AUTOSAR XML (schema 4-0-3)
standard types defined: Boolean, uint8, UInt16, UInt32, UInt8
package /AUTOSAR_Platform/DataConstrs
  range DC_Boolean: raw 0..1
  range DC_UInt16: raw 0..65535
  range DC_UInt8: raw 0..255
package /PATAC/Facility/DataTypes/Implementation
  compu method COMPU_Boolean: 0=FALSE, 1=TRUE
  unit NoUnit: factor-si-to-unit=1, offset-si-to-unit=0
package /PATAC/MSM/ComponentTypes
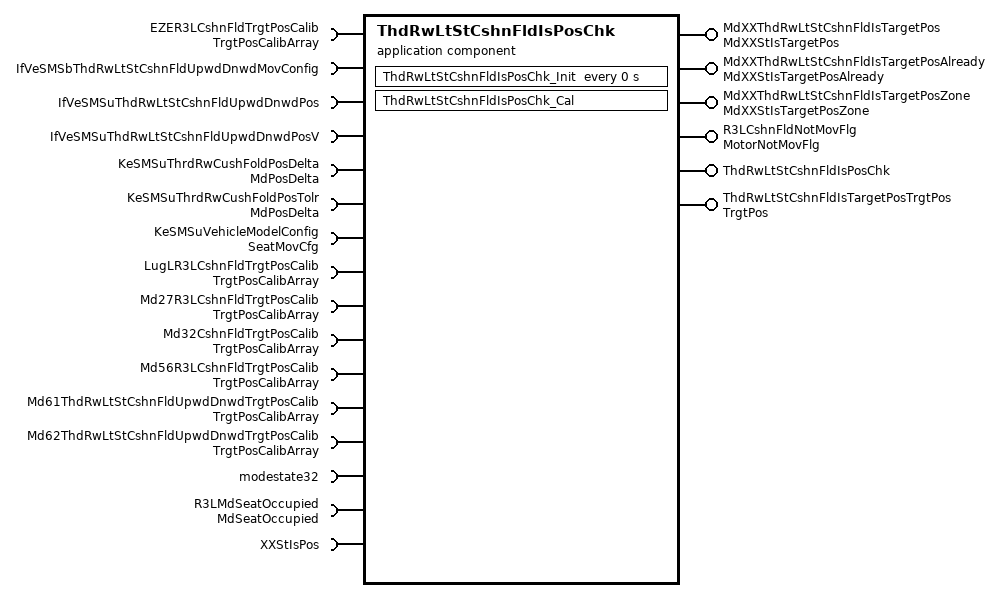
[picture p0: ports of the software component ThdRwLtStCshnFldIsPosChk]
  application sw component type ThdRwLtStCshnFldIsPosChk
    6 x provide port:
      MdXXThdRwLtStCshnFldIsTargetPos: nonqueued-sender-com-spec=data-element=MdXXStIsTargetPos/Val, provided-interface=MdXXStIsTargetPos
      MdXXThdRwLtStCshnFldIsTargetPosAlready: nonqueued-sender-com-spec=data-element=MdXXStIsTargetPosAlready/Val, provided-interface=MdXXStIsTargetPosAlready
      MdXXThdRwLtStCshnFldIsTargetPosZone: nonqueued-sender-com-spec=data-element=MdXXStIsTargetPosZone/Val, provided-interface=MdXXStIsTargetPosZone
      R3LCshnFldNotMovFlg: nonqueued-sender-com-spec{data-element=MotorNotMovFlg/Val, init-value=0}, provided-interface=MotorNotMovFlg
      ThdRwLtStCshnFldIsPosChk: server-com-spec{operation=Cal, queue-length=1}, provided-interface=ThdRwLtStCshnFldIsPosChk
      ThdRwLtStCshnFldIsTargetPosTrgtPos: nonqueued-sender-com-spec{data-element=TrgtPos/Val, init-value=4095}, provided-interface=TrgtPos
    16 x require port:
      EZER3LCshnFldTrgtPosCalib: nonqueued-receiver-com-spec{data-element=TrgtPosArray, filter=data-filter-type=ALWAYS, init-value=[4095, 4095, 4095]}, required-interface=TrgtPosCalibArray
      IfVeSMSbThdRwLtStCshnFldUpwdDnwdMovConfig: nonqueued-receiver-com-spec{data-element=IfVeSMSbThdRwLtStCshnFldUpwdDnwdMovConfig/Val, filter=data-filter-type=ALWAYS, init-value=0}, required-interface=IfVeSMSbThdRwLtStCshnFldUpwdDnwdMovConfig
      IfVeSMSuThdRwLtStCshnFldUpwdDnwdPos: nonqueued-receiver-com-spec{data-element=IfVeSMSuThdRwLtStCshnFldUpwdDnwdPos/Val, filter=data-filter-type=ALWAYS, init-value=0}, required-interface=IfVeSMSuThdRwLtStCshnFldUpwdDnwdPos
      IfVeSMSuThdRwLtStCshnFldUpwdDnwdPosV: nonqueued-receiver-com-spec{data-element=IfVeSMSuThdRwLtStCshnFldUpwdDnwdPosV/Val, filter=data-filter-type=ALWAYS, init-value=0}, required-interface=IfVeSMSuThdRwLtStCshnFldUpwdDnwdPosV
      KeSMSuThrdRwCushFoldPosDelta: parameter-require-com-spec{init-value=150, parameter=MdPosDelta/Val}, required-interface=MdPosDelta
      KeSMSuThrdRwCushFoldPosTolr: parameter-require-com-spec{init-value=150, parameter=MdPosDelta/Val}, required-interface=MdPosDelta
      KeSMSuVehicleModelConfig: parameter-require-com-spec{init-value=2, parameter=SeatMovCfg/Val}, required-interface=SeatMovCfg
      LugLR3LCshnFldTrgtPosCalib: nonqueued-receiver-com-spec{data-element=TrgtPosArray, filter=data-filter-type=ALWAYS, init-value=[4095, 4095, 4095]}, required-interface=TrgtPosCalibArray
      Md27R3LCshnFldTrgtPosCalib: nonqueued-receiver-com-spec{data-element=TrgtPosArray, filter=data-filter-type=ALWAYS, init-value=[4095, 4095, 4095]}, required-interface=TrgtPosCalibArray
      Md32CshnFldTrgtPosCalib: nonqueued-receiver-com-spec{data-element=TrgtPosArray, filter=data-filter-type=ALWAYS, init-value=[4095, 4095, 4095]}, required-interface=TrgtPosCalibArray
      Md56R3LCshnFldTrgtPosCalib: nonqueued-receiver-com-spec{data-element=TrgtPosArray, filter=data-filter-type=ALWAYS, init-value=[4095, 4095, 4095]}, required-interface=TrgtPosCalibArray
      Md61ThdRwLtStCshnFldUpwdDnwdTrgtPosCalib: nonqueued-receiver-com-spec{data-element=TrgtPosArray, filter=data-filter-type=ALWAYS, init-value=[4095, 4095, 4095]}, required-interface=TrgtPosCalibArray
      Md62ThdRwLtStCshnFldUpwdDnwdTrgtPosCalib: nonqueued-receiver-com-spec{data-element=TrgtPosArray, filter=data-filter-type=ALWAYS, init-value=[4095, 4095, 4095]}, required-interface=TrgtPosCalibArray
      modestate32: nonqueued-receiver-com-spec{data-element=modestate32/Val, filter=data-filter-type=ALWAYS, init-value=0}, required-interface=modestate32
      R3LMdSeatOccupied: nonqueued-receiver-com-spec{data-element=MdSeatOccupied/Val, filter=data-filter-type=ALWAYS, init-value=0}, required-interface=MdSeatOccupied
      XXStIsPos: client-com-spec=Get, required-interface=XXStIsPos
    behavior ThdRwLtStCshnFldIsPosChk_InternalBehavior
      operation invoked event OIT_ThdRwLtStCshnFldIsPosChk_Cal_ThdRwLtStCshnFldIsPosChk_Cal: start-on-event=ThdRwLtStCshnFldIsPosChk_Cal, operation=ThdRwLtStCshnFldIsPosChk.Cal
      timing event ThdRwLtStCshnFldIsPosChk_InitEvent: start-on-event=ThdRwLtStCshnFldIsPosChk_Init, period=0
      runnable ThdRwLtStCshnFldIsPosChk_Cal
        data-receive-point-by-arguments:
          12 x access:
            REC_EZER3LCshnFldTrgtPosCalib_TrgtPosArray: accessed-variable=EZER3LCshnFldTrgtPosCalib.TrgtPosArray
            REC_IfVeSMSbThdRwLtStCshnFldUpwdDnwdMovConfig_Val: accessed-variable=IfVeSMSbThdRwLtStCshnFldUpwdDnwdMovConfig.Val
            REC_IfVeSMSuThdRwLtStCshnFldUpwdDnwdPos_Val: accessed-variable=IfVeSMSuThdRwLtStCshnFldUpwdDnwdPos.Val
            REC_IfVeSMSuThdRwLtStCshnFldUpwdDnwdPosV_Val: accessed-variable=IfVeSMSuThdRwLtStCshnFldUpwdDnwdPosV.Val
            REC_LugLR3LCshnFldTrgtPosCalib_TrgtPosArray: accessed-variable=LugLR3LCshnFldTrgtPosCalib.TrgtPosArray
            REC_Md27R3LCshnFldTrgtPosCalib_TrgtPosArray: accessed-variable=Md27R3LCshnFldTrgtPosCalib.TrgtPosArray
            REC_Md32CshnFldTrgtPosCalib_TrgtPosArray: accessed-variable=Md32CshnFldTrgtPosCalib.TrgtPosArray
            REC_Md56R3LCshnFldTrgtPosCalib_TrgtPosArray: accessed-variable=Md56R3LCshnFldTrgtPosCalib.TrgtPosArray
            REC_Md61ThdRwLtStCshnFldUpwdDnwdTrgtPosCalib_TrgtPosArray: accessed-variable=Md61ThdRwLtStCshnFldUpwdDnwdTrgtPosCalib.TrgtPosArray
            REC_Md62ThdRwLtStCshnFldUpwdDnwdTrgtPosCalib_TrgtPosArray: accessed-variable=Md62ThdRwLtStCshnFldUpwdDnwdTrgtPosCalib.TrgtPosArray
            REC_modestate32_Val: accessed-variable=modestate32.Val
            REC_R3LMdSeatOccupied_Val: accessed-variable=R3LMdSeatOccupied.Val
        data-send-points:
          5 x access:
            SEND_MdXXThdRwLtStCshnFldIsTargetPos_Val: accessed-variable=MdXXThdRwLtStCshnFldIsTargetPos.Val
            SEND_MdXXThdRwLtStCshnFldIsTargetPosAlready_Val: accessed-variable=MdXXThdRwLtStCshnFldIsTargetPosAlready.Val
            SEND_MdXXThdRwLtStCshnFldIsTargetPosZone_Val: accessed-variable=MdXXThdRwLtStCshnFldIsTargetPosZone.Val
            SEND_R3LCshnFldNotMovFlg_Val: accessed-variable=R3LCshnFldNotMovFlg.Val
            SEND_ThdRwLtStCshnFldIsTargetPosTrgtPos_Val: accessed-variable=ThdRwLtStCshnFldIsTargetPosTrgtPos.Val
        parameter access PA_KeSMSuThrdRwCushFoldPosDelta_Val: accessed-parameter=KeSMSuThrdRwCushFoldPosDelta.Val
        parameter access PA_KeSMSuThrdRwCushFoldPosTolr_Val: accessed-parameter=KeSMSuThrdRwCushFoldPosTolr.Val
        parameter access PA_KeSMSuVehicleModelConfig_Val: accessed-parameter=KeSMSuVehicleModelConfig.Val
        sync call SC_XXStIsPos_Get: operation=XXStIsPos.Get, timeout=0
      runnable ThdRwLtStCshnFldIsPosChk_Init
        parameter access PA_KeSMSuThrdRwCushFoldPosDelta_Val: accessed-parameter=KeSMSuThrdRwCushFoldPosDelta.Val
        parameter access PA_KeSMSuThrdRwCushFoldPosTolr_Val: accessed-parameter=KeSMSuThrdRwCushFoldPosTolr.Val
        parameter access PA_KeSMSuVehicleModelConfig_Val: accessed-parameter=KeSMSuVehicleModelConfig.Val
  swc implementation ThdRwLtStCshnFldIsPosChk_Implementation: behavior=ThdRwLtStCshnFldIsPosChk_InternalBehavior
    code-descriptors:
      code Default: artifact-descriptors=autosar-engineering-object={short-label=Default, category=SWSRC}
package /PATAC/MSM/DataTypes
  parameter interface SeatMovCfg
    parameter data prototype Val: sw-calibration-access=READ-WRITE, type=UInt8
package /PATAC/MSM/ModeAdjust/CalPortInterface
  parameter interface MdPosDelta
    parameter data prototype Val: sw-calibration-access=READ-WRITE, type=UInt16
package /PATAC/MSM/ModeAdjust/DataType
  impl type TrgtPosCalibArray: category=ARRAY, sw-calibration-access=READ-ONLY, type-emitter=RTE  # 0:pos 1:max 2:min
    element Element: array-size=3, array-size-semantics=FIXED-SIZE, implementation-data-type=UInt16, invalid-value=0
package /PATAC/MSM/ModeAdjust/Interfaces
  sender receiver interface IfVeSMSuThdRwLtStCshnFldUpwdDnwdPos: invalidation-policy{data-element=IfVeSMSuThdRwLtStCshnFldUpwdDnwdPos/Val, handle-invalid=DONT-INVALIDATE}
    data Val: type=UInt16
  sender receiver interface IfVeSMSuThdRwLtStCshnFldUpwdDnwdPosV: invalidation-policy{data-element=IfVeSMSuThdRwLtStCshnFldUpwdDnwdPosV/Val, handle-invalid=DONT-INVALIDATE}
    data Val: type=Implementation/Boolean
package /PATAC/MSM/ModeAdjust/PortInterface
  client server interface ThdRwLtStCshnFldIsPosChk
    operation Cal
  client server interface XXStIsPos
    operation Get
      8 x arg, all with server-argument-impl-policy=USE-ARGUMENT-TYPE:
        PosV: type=DataTypes/Boolean, direction=IN
        Pos: type=UInt16, direction=IN
        CalibArray: type=TrgtPosCalibArray, direction=IN
        Delta: type=UInt16, direction=IN
        Tolr: type=UInt16, direction=IN
        IsPos: type=DataTypes/Boolean, direction=OUT
        IsPosZone: type=DataTypes/Boolean, direction=OUT
        IsPosAlready: type=DataTypes/Boolean, direction=OUT
  7 x sender receiver interface:
    MdSeatOccupied: invalidation-policy{data-element=MdSeatOccupied/Val, handle-invalid=DONT-INVALIDATE}
      data Val: type=Implementation/Boolean
    MdXXStIsTargetPos: invalidation-policy{data-element=MdXXStIsTargetPos/Val, handle-invalid=DONT-INVALIDATE}
      data Val: type=UInt32
    MdXXStIsTargetPosAlready: invalidation-policy{data-element=MdXXStIsTargetPosAlready/Val, handle-invalid=DONT-INVALIDATE}
      data Val: type=UInt32
    MdXXStIsTargetPosZone: invalidation-policy{data-element=MdXXStIsTargetPosZone/Val, handle-invalid=DONT-INVALIDATE}
      data Val: type=UInt32
    modestate32: invalidation-policy{data-element=modestate32/Val, handle-invalid=DONT-INVALIDATE}
      data Val: type=UInt32
    MotorNotMovFlg: invalidation-policy{data-element=MotorNotMovFlg/Val, handle-invalid=DONT-INVALIDATE}
      data Val: type=Implementation/Boolean
    TrgtPosCalibArray: invalidation-policy{data-element=TrgtPosArray, handle-invalid=DONT-INVALIDATE}
      data TrgtPosArray: type=TrgtPosCalibArray  # 0:Pos 1:Max 2:Min
package /PATAC/MSM/PortInterfaces
  sender receiver interface IfVeSMSbThdRwLtStCshnFldUpwdDnwdMovConfig: invalidation-policy{data-element=IfVeSMSbThdRwLtStCshnFldUpwdDnwdMovConfig/Val, handle-invalid=DONT-INVALIDATE}
    data Val: type=Implementation/Boolean
  sender receiver interface TrgtPos: invalidation-policy{data-element=TrgtPos/Val, handle-invalid=DONT-INVALIDATE}
    data Val: type=UInt16
